VERSION ""

NS_ :

BS_:

BU_:
VAL_TABLE_ vFAULTMNGR_GS_NRD_Flt 7 "NA" 6 "reserved5" 5 "reserved4" 4 "reserved3" 3 "reserved2" 2 "reserved1" 1 "FAULTMNGR_GS_NRD_Fault" 0 "FAULTMNGR_GS_NRD_NoFault" ;
VAL_TABLE_ vFAULTMNGR_GS_ML_Flt 7 "NA" 6 "FAULTMNGR_GS_ML_OutofRange" 5 "FAULTMNGR_GS_ML_GSCommandInvalid" 4 "FAULTMNGR_GS_ML_EPBError" 3 "FAULTMNGR_GS_ML_EPBInvalid" 2 "FAULTMNGR_GS_ML_InterlockError" 1 "FAULTMNGR_GS_ML_InterlockInvalid" 0 "FAULTMNGR_GS_ML_NoFault" ;
VAL_TABLE_ vAction_t 0 "va_Off" 1 "va_On" 2 "va_Reserved" 3 "va_Take_no_action" ;
VAL_TABLE_ APP_GS_InvDirEnum_t 1 "MoveBwd" 0 "MoveFwd" ;
VAL_TABLE_ APP_GS_ML_Req_t 3 "NotDefined" 2 "Take_no_action" 1 "Unlocked" 0 "Locked" ;
VAL_TABLE_ gs_mvlksel_t 5 "Take_no_action" 4 "Change_in_Progress" 3 "Error" 2 "N_A" 1 "Unlocked" 0 "Locked" ;
VAL_TABLE_ gs_dbg_t 16 "comGS_Reverse_NoAction" 15 "comGS_Neutral_NoAction" 14 "comGS_Drive_NoAction" 13 "comGS_Error" 12 "comGS_N_A" 11 "comGS_Change_in_Progress" 10 "comGS_Reverse_PErr" 9 "comGS_Drive_PErr" 8 "comGS_Neutral_PErr" 7 "comGS_Park_DT_Err" 6 "comGS_DT_Err" 5 "comGS_ParkReverse" 4 "comGS_ParkDrive" 3 "comGS_Reverse" 2 "comGS_Drive" 1 "comGS_Neutral" 0 "comGS_Park" ;

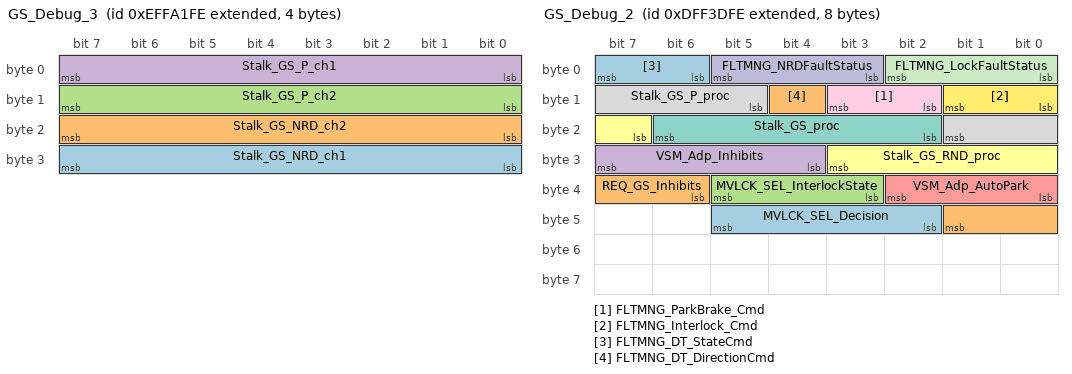
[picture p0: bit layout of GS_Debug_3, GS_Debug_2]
BO_ 2399117822 GS_Debug_3: 4 Vector__XXX
 SG_ Stalk_GS_NRD_ch1 : 24|8@1+ (0.05,0) [0|12] "V" Vector__XXX
 SG_ Stalk_GS_NRD_ch2 : 16|8@1+ (0.05,0) [0|12] "V" Vector__XXX
 SG_ Stalk_GS_P_ch2 : 8|8@1+ (0.05,0) [0|12] "V" Vector__XXX
 SG_ Stalk_GS_P_ch1 : 0|8@1+ (0.05,0) [0|12] "V" Vector__XXX

BO_ 2382315006 GS_Debug_2: 8 Vector__XXX
 SG_ MVLCK_SEL_Decision : 42|4@1+ (1,0) [0|15] "" Vector__XXX
 SG_ REQ_GS_Inhibits : 38|4@1+ (1,0) [0|15] "" Vector__XXX
 SG_ MVLCK_SEL_InterlockState : 35|3@1+ (1,0) [0|5] "" Vector__XXX
 SG_ VSM_Adp_Inhibits : 28|4@1+ (1,0) [0|15] "" Vector__XXX
 SG_ VSM_Adp_AutoPark : 32|3@1+ (1,0) [0|7] "" Vector__XXX
 SG_ Stalk_GS_RND_proc : 23|5@1+ (1,0) [0|31] "" Vector__XXX
 SG_ Stalk_GS_proc : 18|5@1+ (1,0) [0|31] "" Vector__XXX
 SG_ Stalk_GS_P_proc : 13|5@1+ (1,0) [0|31] "" Vector__XXX
 SG_ FLTMNG_ParkBrake_Cmd : 10|2@1+ (1,0) [0|0] "" Vector__XXX
 SG_ FLTMNG_NRDFaultStatus : 3|3@1+ (1,0) [0|0] "" Vector__XXX
 SG_ FLTMNG_LockFaultStatus : 0|3@1+ (1,0) [0|0] "" Vector__XXX
 SG_ FLTMNG_Interlock_Cmd : 8|2@1+ (1,0) [0|0] "" Vector__XXX
 SG_ FLTMNG_DT_StateCmd : 6|2@1+ (1,0) [0|0] "" Vector__XXX
 SG_ FLTMNG_DT_DirectionCmd : 12|1@1+ (1,0) [0|0] "" Vector__XXX

BO_ 2382314750 GS_Debug_1: 8 Vector__XXX
 SG_ Stalk_GS_P_valid : 55|1@1+ (1,0) [0|1] "" Vector__XXX
 SG_ Stalk_GS_NRD_valid : 47|1@1+ (1,0) [0|1] "" Vector__XXX
 SG_ EmcyDecelCmd : 7|1@1+ (1,0) [0|0] "" Vector__XXX
 SG_ MVLCK_SEL_GBIntlckReq : 58|3@1+ (1,0) [0|0] "" Vector__XXX
 SG_ MVLCK_SEL_PBKState : 13|3@1+ (1,0) [0|0] "" Vector__XXX
 SG_ INIT_GS_VehMvFwdFlag : 6|1@1+ (1,0) [0|0] "" Vector__XXX
 SG_ APP_GS_InvDirReq : 54|1@1+ (1,0) [0|0] "" Vector__XXX
 SG_ APP_GS_InvActReq : 53|1@1+ (1,0) [0|0] "" Vector__XXX
 SG_ APP_GS_MvLckReq : 56|2@1+ (1,0) [0|0] "" Vector__XXX
 SG_ MVLCK_SEL_State : 21|3@1+ (1,0) [0|0] "" Vector__XXX
 SG_ MVLCK_SEL_PBKReq : 61|3@1+ (1,0) [0|0] "" Vector__XXX
 SG_ Stalk_GS_valid : 46|1@1+ (1,0) [0|0] "" Vector__XXX
 SG_ Stalk_GS_RND_event : 44|1@1+ (1,0) [0|0] "" Vector__XXX
 SG_ Stalk_GS_LongPressedP : 45|1@1+ (1,0) [0|0] "" Vector__XXX
 SG_ Stalk_GS_NRD_state : 40|3@1+ (1,0) [0|0] "" Vector__XXX
 SG_ Stalk_GS_P_button : 43|1@1+ (1,0) [0|0] "" Vector__XXX
 SG_ Stalk_GS_Req : 48|5@1+ (1,0) [0|31] "" Vector__XXX
 SG_ EXHAN_VSMGSReq : 8|5@1+ (1,0) [0|31] "" Vector__XXX
 SG_ EXHAN_GS_AllowReqVec : 24|8@1+ (1,0) [0|255] "" Vector__XXX
 SG_ EXHAN_ChsnGSReqValid : 5|1@1+ (1,0) [0|1] "" Vector__XXX
 SG_ EXHAN_ChsnGSReq : 0|5@1+ (1,0) [0|31] "" Vector__XXX
 SG_ EXHAN_FinalGSReq : 16|5@1+ (1,0) [0|31] "" Vector__XXX
 SG_ EXHAN_ActCondition : 36|4@1+ (1,0) [0|15] "" Vector__XXX
 SG_ EXHAN_ActScenario : 32|4@1+ (1,0) [0|15] "" Vector__XXX

CM_ BO_ 2399117822 "For DEBUG-TEST only! Consist of signals that can replace AI GS Request, HMI 3 GS Request and state of gearbox interlock signals.";
CM_ SG_ 2399117822 Stalk_GS_NRD_ch1 "Stalk_GS_NRD_ch1";
CM_ SG_ 2399117822 Stalk_GS_NRD_ch2 "Stalk_GS_NRD_ch2";
CM_ SG_ 2399117822 Stalk_GS_P_ch2 "Stalk_GS_P_ch2";
CM_ SG_ 2399117822 Stalk_GS_P_ch1 "Stalk_GS_P_ch1";
CM_ BO_ 2382315006 "For DEBUG-TEST only! Consist of signals that can replace AI GS Request, HMI 3 GS Request and state of gearbox interlock signals.";
CM_ SG_ 2382315006 FLTMNG_ParkBrake_Cmd "FAULTMNGR_GS: ParkBrake_Cmd_Safe";
CM_ SG_ 2382315006 FLTMNG_Interlock_Cmd "FAULTMNGR_GS: Interlock_Cmd_Safe";
CM_ SG_ 2382315006 FLTMNG_DT_StateCmd "FAULTMNGR_GS: DT_StateCmd_Safe";
CM_ SG_ 2382315006 FLTMNG_DT_DirectionCmd "FAULTMNGR_GS: DT_DirectionCmd";
CM_ BO_ 2382314750 "For DEBUG-TEST only! Consist of signals that can replace AI GS Request, HMI 3 GS Request and state of gearbox interlock signals.";
CM_ SG_ 2382314750 Stalk_GS_P_valid "Request of P button is valid or not";
CM_ SG_ 2382314750 Stalk_GS_NRD_valid "Request of NRD stalk is valid or not";
CM_ SG_ 2382314750 Stalk_GS_NRD_state "1-R,  2 - N, 4 - D, 6 - NOT VALID";
CM_ SG_ 2382314750 Stalk_GS_Req "Flag  of the AI request inaccessibility. If it is true then AI GS request signal is valid but not correct in current circumstances";
CM_ SG_ 2382314750 EXHAN_VSMGSReq "Flag  of the AI request inaccessibility. If it is true then AI GS request signal is valid but not correct in current circumstances";
CM_ SG_ 2382314750 EXHAN_GS_AllowReqVec "[1- P; 2 - N; 3 - D; 4 - R; 5 - PD; 6  - PR] each element signalize about the allowance of particular state via true value
";
CM_ SG_ 2382314750 EXHAN_ChsnGSReqValid "Flag  of the AI request inaccessibility. If it is true then AI GS request signal is valid but not correct in current circumstances";
CM_ SG_ 2382314750 EXHAN_ChsnGSReq "Flag  of the AI request inaccessibility. If it is true then AI GS request signal is valid but not correct in current circumstances";
CM_ SG_ 2382314750 EXHAN_FinalGSReq "Flag  of the AI request inaccessibility. If it is true then AI GS request signal is valid but not correct in current circumstances";
CM_ SG_ 2382314750 EXHAN_ActCondition "Flag  of the AI request inaccessibility. If it is true then AI GS request signal is valid but not correct in current circumstances";
CM_ SG_ 2382314750 EXHAN_ActScenario "Flag  of the AI request inaccessibility. If it is true then AI GS request signal is valid but not correct in current circumstances";
BA_DEF_ BO_  "SendOnChange" ENUM  "No","Yes";
BA_DEF_ BO_  "Producer" STRING ;
BA_DEF_ SG_  "SigType" ENUM  "Default","Range","RangeSigned","ASCII","Discrete","Control","ReferencePGN","DTC","StringDelimiter","StringLength","StringLengthControl","MessageCounter","MessageChecksum";
BA_DEF_ SG_  "GenSigEVName" STRING ;
BA_DEF_ SG_  "GenSigILSupport" ENUM  "No","Yes";
BA_DEF_ SG_  "GenSigSendType" ENUM  "Cyclic","OnWrite","OnWriteWithRepetition","OnChange","OnChangeWithRepetition","IfActive","IfActiveWithRepetition","NoSigSendType";
BA_DEF_ BO_  "GenMsgDelayTime" INT 0 1000;
BA_DEF_ BO_  "GenMsgILSupport" ENUM  "No","Yes";
BA_DEF_ BU_  "NmStationAddress" INT 0 255;
BA_DEF_ BO_  "GenMsgSendType" ENUM  "cyclic","NotUsed","IfActive","NotUsed","NotUsed","NotUsed","NotUsed","NotUsed","noMsgSendType";
BA_DEF_ BO_  "GenMsgRequestable" INT 0 1;
BA_DEF_ BO_  "GenMsgCycleTime" INT 0 3600000;
BA_DEF_  "DBName" STRING ;
BA_DEF_  "BusType" STRING ;
BA_DEF_  "ProtocolType" STRING ;
BA_DEF_ BO_  "VFrameFormat" ENUM  "StandardCAN","ExtendedCAN","reserved","J1939PG";
BA_DEF_DEF_  "SendOnChange" "No";
BA_DEF_DEF_ "Producer" "DTS" ;
BA_DEF_DEF_  "SigType" "Default";
BA_DEF_DEF_  "GenSigEVName" "Env@Nodename_@Signame";
BA_DEF_DEF_  "GenSigILSupport" "Yes";
BA_DEF_DEF_  "GenSigSendType" "NoSigSendType";
BA_DEF_DEF_  "GenMsgDelayTime" 0;
BA_DEF_DEF_  "GenMsgILSupport" "Yes";
BA_DEF_DEF_  "NmStationAddress" 254;
BA_DEF_DEF_  "GenMsgSendType" "noMsgSendType";
BA_DEF_DEF_  "GenMsgRequestable" 1;
BA_DEF_DEF_  "GenMsgCycleTime" 0;
BA_DEF_DEF_  "DBName" "";
BA_DEF_DEF_  "BusType" "CAN";
BA_DEF_DEF_  "ProtocolType" "J1939";
BA_DEF_DEF_  "VFrameFormat" "J1939PG";
BA_ "DBName" "GearSelector";
BA_ "GenMsgDelayTime" BO_ 2399117822 50;
BA_ "SendOnChange" BO_ 2399117822 1;
BA_ "GenMsgCycleTime" BO_ 2399117822 1000;
BA_ "GenMsgSendType" BO_ 2399117822 0;
BA_ "SendOnChange" BO_ 2382315006 1;
BA_ "GenMsgCycleTime" BO_ 2382315006 100;
BA_ "GenMsgSendType" BO_ 2382315006 0;
BA_ "GenMsgCycleTime" BO_ 2382314750 200;
BA_ "GenMsgSendType" BO_ 2382314750 0;
VAL_ 2382315006 REQ_GS_Inhibits 9 "NA" 8 "Error" 7 "PRNDInhibitDrvrPres" 6 "PBrakeInhib" 5 "PSpeedInhib" 4 "NBrakeInhib" 3 "RDBrakeInhib" 2 "RDAccPedInhib" 1 "RDNrdAccInhib" 0 "NoNotification" ;
VAL_ 2382315006 MVLCK_SEL_InterlockState 5 "Disabled" 4 "Change_in_Progress" 3 "Error" 2 "N_A" 1 "Unlocked" 0 "Locked" ;
VAL_ 2382315006 VSM_Adp_Inhibits 15 "NA" 14 "NVSMInhib" 13 "NDriverNotReadyAutoParkInhib" 12 "NImmoAutoParkInhib" 11 "NDoorAutoParkInhib" 10 "NChrgPlugAutoParkInhib" 9 "RDVSMInhib" 8 "RDDriverNotReadyAutoParkInhib" 7 "RDImmoAutoParkInhib" 6 "RDDoorAutoParkInhib" 5 "RDChrgPlugAutoParkInhib" 4 "RDSpeedInhib" 3 "RDChargInhib" 2 "RDRampInhib" 1 "RDDoorInhib" 0 "NoVSMNotif" ;
VAL_ 2382315006 VSM_Adp_AutoPark 6 "NA" 5 "DriverNotReady" 4 "Immo" 3 "DoorEvent" 2 "DoorConst" 1 "ChrgPlug" 0 "NoVSMNotif" ;
VAL_ 2382315006 Stalk_GS_RND_proc 16 "comGS_Reverse_NoAction" 15 "comGS_Neutral_NoAction" 14 "comGS_Drive_NoAction" 13 "comGS_Error" 12 "comGS_N_A" 11 "comGS_Change_in_Progress" 10 "comGS_Reverse_PErr" 9 "comGS_Drive_PErr" 8 "comGS_Neutral_PErr" 7 "comGS_Park_DT_Err" 6 "comGS_DT_Err" 5 "comGS_ParkReverse" 4 "comGS_ParkDrive" 3 "comGS_Reverse" 2 "comGS_Drive" 1 "comGS_Neutral" 0 "comGS_Park" ;
VAL_ 2382315006 Stalk_GS_proc 16 "comGS_Reverse_NoAction" 15 "comGS_Neutral_NoAction" 14 "comGS_Drive_NoAction" 13 "comGS_Error" 12 "comGS_N_A" 11 "comGS_Change_in_Progress" 10 "comGS_Reverse_PErr" 9 "comGS_Drive_PErr" 8 "comGS_Neutral_PErr" 7 "comGS_Park_DT_Err" 6 "comGS_DT_Err" 5 "comGS_ParkReverse" 4 "comGS_ParkDrive" 3 "comGS_Reverse" 2 "comGS_Drive" 1 "comGS_Neutral" 0 "comGS_Park" ;
VAL_ 2382315006 Stalk_GS_P_proc 16 "comGS_Reverse_NoAction" 15 "comGS_Neutral_NoAction" 14 "comGS_Drive_NoAction" 13 "comGS_Error" 12 "comGS_N_A" 11 "comGS_Change_in_Progress" 10 "comGS_Reverse_PErr" 9 "comGS_Drive_PErr" 8 "comGS_Neutral_PErr" 7 "comGS_Park_DT_Err" 6 "comGS_DT_Err" 5 "comGS_ParkReverse" 4 "comGS_ParkDrive" 3 "comGS_Reverse" 2 "comGS_Drive" 1 "comGS_Neutral" 0 "comGS_Park" ;
VAL_ 2382315006 FLTMNG_ParkBrake_Cmd 0 "va_Off" 1 "va_On" 2 "va_Reserved" 3 "va_Take_no_action" ;
VAL_ 2382315006 FLTMNG_NRDFaultStatus 7 "NA" 6 "reserved5" 5 "reserved4" 4 "reserved3" 3 "reserved2" 2 "reserved1" 1 "FAULTMNGR_GS_NRD_Fault" 0 "FAULTMNGR_GS_NRD_NoFault" ;
VAL_ 2382315006 FLTMNG_LockFaultStatus 7 "NA" 6 "FAULTMNGR_GS_ML_OutofRange" 5 "FAULTMNGR_GS_ML_GSCommandInvalid" 4 "FAULTMNGR_GS_ML_EPBError" 3 "FAULTMNGR_GS_ML_EPBInvalid" 2 "FAULTMNGR_GS_ML_InterlockError" 1 "FAULTMNGR_GS_ML_InterlockInvalid" 0 "FAULTMNGR_GS_ML_NoFault" ;
VAL_ 2382315006 FLTMNG_Interlock_Cmd 0 "va_Off" 1 "va_On" 2 "va_Reserved" 3 "va_Take_no_action" ;
VAL_ 2382315006 FLTMNG_DT_StateCmd 0 "va_Off" 1 "va_On" 2 "va_Reserved" 3 "va_Take_no_action" ;
VAL_ 2382314750 MVLCK_SEL_GBIntlckReq 5 "Take_no_action" 4 "Change_in_Progress" 3 "Error" 2 "N_A" 1 "Unlocked" 0 "Locked" ;
VAL_ 2382314750 MVLCK_SEL_PBKState 5 "Take_no_action" 4 "Change_in_Progress" 3 "Error" 2 "N_A" 1 "Unlocked" 0 "Locked" ;
VAL_ 2382314750 APP_GS_InvDirReq 1 "MoveBwd" 0 "MoveFwd" ;
VAL_ 2382314750 APP_GS_MvLckReq 3 "NotDefined" 2 "Take_no_action" 1 "Unlocked" 0 "Locked" ;
VAL_ 2382314750 MVLCK_SEL_State 5 "Take_no_action" 4 "Change_in_Progress" 3 "Error" 2 "N_A" 1 "Unlocked" 0 "Locked" ;
VAL_ 2382314750 MVLCK_SEL_PBKReq 5 "Take_no_action" 4 "Change_in_Progress" 3 "Error" 2 "N_A" 1 "Unlocked" 0 "Locked" ;
VAL_ 2382314750 Stalk_GS_Req 16 "comGS_Reverse_NoAction" 15 "comGS_Neutral_NoAction" 14 "comGS_Drive_NoAction" 13 "comGS_Error" 12 "comGS_N_A" 11 "comGS_Change_in_Progress" 10 "comGS_Reverse_PErr" 9 "comGS_Drive_PErr" 8 "comGS_Neutral_PErr" 7 "comGS_Park_DT_Err" 6 "comGS_DT_Err" 5 "comGS_ParkReverse" 4 "comGS_ParkDrive" 3 "comGS_Reverse" 2 "comGS_Drive" 1 "comGS_Neutral" 0 "comGS_Park" ;
VAL_ 2382314750 EXHAN_VSMGSReq 16 "comGS_Reverse_NoAction" 15 "comGS_Neutral_NoAction" 14 "comGS_Drive_NoAction" 13 "comGS_Error" 12 "comGS_N_A" 11 "comGS_Change_in_Progress" 10 "comGS_Reverse_PErr" 9 "comGS_Drive_PErr" 8 "comGS_Neutral_PErr" 7 "comGS_Park_DT_Err" 6 "comGS_DT_Err" 5 "comGS_ParkReverse" 4 "comGS_ParkDrive" 3 "comGS_Reverse" 2 "comGS_Drive" 1 "comGS_Neutral" 0 "comGS_Park" ;
VAL_ 2382314750 EXHAN_ChsnGSReq 16 "comGS_Reverse_NoAction" 15 "comGS_Neutral_NoAction" 14 "comGS_Drive_NoAction" 13 "comGS_Error" 12 "comGS_N_A" 11 "comGS_Change_in_Progress" 10 "comGS_Reverse_PErr" 9 "comGS_Drive_PErr" 8 "comGS_Neutral_PErr" 7 "comGS_Park_DT_Err" 6 "comGS_DT_Err" 5 "comGS_ParkReverse" 4 "comGS_ParkDrive" 3 "comGS_Reverse" 2 "comGS_Drive" 1 "comGS_Neutral" 0 "comGS_Park" ;
VAL_ 2382314750 EXHAN_FinalGSReq 16 "comGS_Reverse_NoAction" 15 "comGS_Neutral_NoAction" 14 "comGS_Drive_NoAction" 13 "comGS_Error" 12 "comGS_N_A" 11 "comGS_Change_in_Progress" 10 "comGS_Reverse_PErr" 9 "comGS_Drive_PErr" 8 "comGS_Neutral_PErr" 7 "comGS_Park_DT_Err" 6 "comGS_DT_Err" 5 "comGS_ParkReverse" 4 "comGS_ParkDrive" 3 "comGS_Reverse" 2 "comGS_Drive" 1 "comGS_Neutral" 0 "comGS_Park" ;
